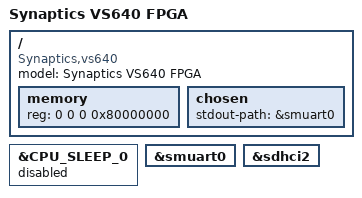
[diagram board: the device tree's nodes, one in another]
/* SPDX-License-Identifier: GPL-2.0+ */
/*
 * Copyright (C) 2020 Synaptics Incorporated
 *
 * Author: Cheng Lu <Cheng.Lu@synaptics.com>
 *
 */

/dts-v1/;

#include "vs640.dtsi"
#include "include/dt-bindings/gpio/gpio.h"

/ {
	model = "Synaptics VS640 FPGA";
	compatible = "Synaptics,vs640", "Synaptics,vsserial";

	memory {
		device_type = "memory";
		reg = <0 0 0 0x80000000>;
	};

	chosen {
		stdout-path = &smuart0;
	};
};

&CPU_SLEEP_0 {
	status = "disabled";
};

&smuart0 {
	status = "okay";
};

&sdhci2 {
	status = "okay";
};
